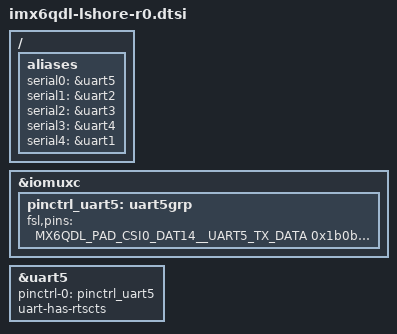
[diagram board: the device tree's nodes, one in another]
/*
 * Copyright 2017 Boundary Devices
 *
 * The code contained herein is licensed under the GNU General Public
 * License. You may obtain a copy of the GNU General Public License
 * Version 2 or later at the following locations:
 *
 * http://www.opensource.org/licenses/gpl-license.html
 * http://www.gnu.org/copyleft/gpl.html
 */

#include "imx6qdl-lshore.dtsi"

&iomuxc {
	pinctrl_uart5: uart5grp {
		fsl,pins = <
			MX6QDL_PAD_CSI0_DAT14__UART5_TX_DATA	0x1b0b1
			MX6QDL_PAD_CSI0_DAT15__UART5_RX_DATA	0x1b0b1
			MX6QDL_PAD_CSI0_DAT19__UART5_CTS_B	0x1b0b1
			MX6QDL_PAD_CSI0_DAT18__UART5_RTS_B	0x1b0b1
		>;
	};
};

/ {
	aliases {
                serial0 = &uart5;
                serial1 = &uart2;
                serial2 = &uart3;
                serial3 = &uart4;
                serial4 = &uart1;
	};
};

&uart5 {
	pinctrl-names = "default";
	pinctrl-0 = <&pinctrl_uart5>;
	uart-has-rtscts;
	status = "okay";
};
